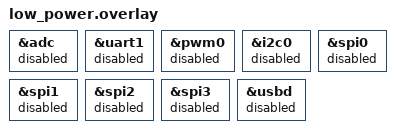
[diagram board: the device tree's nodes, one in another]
/*
 * Copyright (c) 2023 Nordic Semiconductor ASA
 *
 * SPDX-License-Identifier: LicenseRef-Nordic-5-Clause
 */

&adc {
	status = "disabled";
};
&uart1 {
	status = "disabled";
};
&pwm0 {
	status = "disabled";
};
&i2c0 {
	status = "disabled";
};
&spi0 {
	status = "disabled";
};
&spi1 {
	status = "disabled";
};
&spi2 {
	status = "disabled";
};
&spi3 {
	status = "disabled";
};
&usbd {
	status = "disabled";
};
